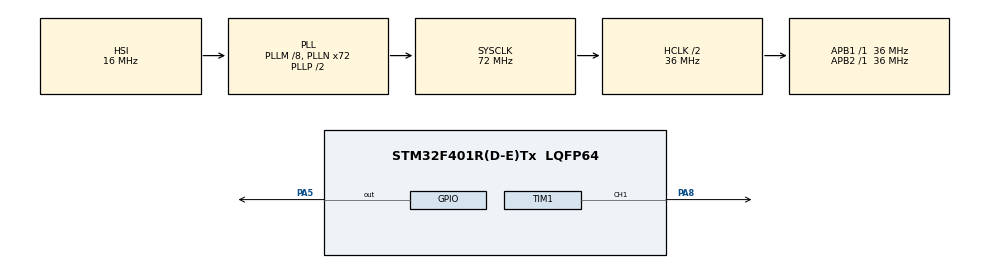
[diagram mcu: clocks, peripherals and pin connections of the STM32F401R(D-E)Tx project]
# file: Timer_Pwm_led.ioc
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Mcu.Family=STM32F4
Mcu.Name=STM32F401R(D-E)Tx
Mcu.Package=LQFP64
NVIC.PriorityGroup=NVIC_PRIORITYGROUP_4
PA13.Mode=Serial_Wire
PA13.Signal=SYS_JTMS-SWDIO
PA14.Mode=Serial_Wire
PA14.Signal=SYS_JTCK-SWCLK
PA5.Signal=GPIO_Output
PA8.Signal=S_TIM1_CH1
PH0\ -\ OSC_IN.Mode=HSE-External-Clock-Source
PH0\ -\ OSC_IN.Signal=RCC_OSC_IN
PH1\ -\ OSC_OUT.Mode=HSE-External-Clock-Source
PH1\ -\ OSC_OUT.Signal=RCC_OSC_OUT
ProjectManager.HeapSize=0x200
ProjectManager.StackSize=0x400
ProjectManager.TargetToolchain=STM32CubeIDE
RCC.48MHZClocksFreq_Value=36000000
RCC.AHBCLKDivider=RCC_SYSCLK_DIV2
RCC.AHBFreq_Value=36000000
RCC.APB1Freq_Value=36000000
RCC.APB1TimFreq_Value=36000000
RCC.APB2Freq_Value=36000000
RCC.APB2TimFreq_Value=36000000
RCC.CortexFreq_Value=36000000
RCC.HCLKFreq_Value=36000000
RCC.HSE_VALUE=25000000
RCC.HSI_VALUE=16000000
RCC.LSE_VALUE=32768
RCC.PLLM=8
RCC.PLLN=72
RCC.SYSCLKFreq_VALUE=72000000
RCC.SYSCLKSource=RCC_SYSCLKSOURCE_PLLCLK
RCC.VCOOutputFreq_Value=144000000
SH.S_TIM1_CH1.0=TIM1_CH1,PWM Generation1 CH1
TIM1.Channel-PWM\ Generation1\ CH1=TIM_CHANNEL_1
board=custom

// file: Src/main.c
/* USER CODE BEGIN Header */
/**
  ******************************************************************************
  * @file           : main.c
  * @brief          : Main program body
  ******************************************************************************
  * @attention
  *
  * <h2><center>&copy; Copyright (c) 2021 STMicroelectronics.
  * All rights reserved.</center></h2>
  *
  * This software component is licensed by ST under BSD 3-Clause license,
  * the "License"; You may not use this file except in compliance with the
  * License. You may obtain a copy of the License at:
  *                        opensource.org/licenses/BSD-3-Clause
  *
  ******************************************************************************
  */
/* USER CODE END Header */
#include "main.h"

TIM_HandleTypeDef htim1;

void SystemClock_Config(void);
static void MX_GPIO_Init(void);
static void MX_TIM1_Init(void);

/* USER CODE BEGIN 0 */
int32_t bright=0;

/* USER CODE END 0 */

int main(void)
{

  /* MCU Configuration--------------------------------------------------------*/

  /* Reset of all peripherals, Initializes the Flash interface and the Systick. */
  HAL_Init();

  /* Configure the system clock */
  SystemClock_Config();

  /* Initialize all configured peripherals */
  MX_GPIO_Init();
  MX_TIM1_Init();
  /* USER CODE BEGIN 2 */

  HAL_TIM_PWM_Start(&htim1, TIM_CHANNEL_1);

  /* USER CODE END 2 */

  /* Infinite loop */
  while (1)
  {

    /* USER CODE BEGIN 3 */
	  while(bright < htim1.Init.Period){

	 	  bright+=100;
	 	  __HAL_TIM_SET_COMPARE(&htim1,TIM_CHANNEL_1,bright);

	 	  HAL_Delay(1);
	 	  }
	 	  while(bright > 0){
	 		  bright-=100;
	 		  __HAL_TIM_SET_COMPARE(&htim1,TIM_CHANNEL_1,bright);

	 		  HAL_Delay(1);
	 	  }

  }
  /* USER CODE END 3 */
}

void SystemClock_Config(void)
{
  RCC_OscInitTypeDef RCC_OscInitStruct = {0};
  RCC_ClkInitTypeDef RCC_ClkInitStruct = {0};

  /** Configure the main internal regulator output voltage
  */
  __HAL_RCC_PWR_CLK_ENABLE();
  __HAL_PWR_VOLTAGESCALING_CONFIG(PWR_REGULATOR_VOLTAGE_SCALE2);
  /** Initializes the RCC Oscillators according to the specified parameters
  * in the RCC_OscInitTypeDef structure.
  */
  RCC_OscInitStruct.OscillatorType = RCC_OSCILLATORTYPE_HSI;
  RCC_OscInitStruct.HSIState = RCC_HSI_ON;
  RCC_OscInitStruct.HSICalibrationValue = RCC_HSICALIBRATION_DEFAULT;
  RCC_OscInitStruct.PLL.PLLState = RCC_PLL_ON;
  RCC_OscInitStruct.PLL.PLLSource = RCC_PLLSOURCE_HSI;
  RCC_OscInitStruct.PLL.PLLM = 8;
  RCC_OscInitStruct.PLL.PLLN = 72;
  RCC_OscInitStruct.PLL.PLLP = RCC_PLLP_DIV2;
  RCC_OscInitStruct.PLL.PLLQ = 4;
  if (HAL_RCC_OscConfig(&RCC_OscInitStruct) != HAL_OK)
  {
    Error_Handler();
  }
  /** Initializes the CPU, AHB and APB buses clocks
  */
  RCC_ClkInitStruct.ClockType = RCC_CLOCKTYPE_HCLK|RCC_CLOCKTYPE_SYSCLK
                              |RCC_CLOCKTYPE_PCLK1|RCC_CLOCKTYPE_PCLK2;
  RCC_ClkInitStruct.SYSCLKSource = RCC_SYSCLKSOURCE_PLLCLK;
  RCC_ClkInitStruct.AHBCLKDivider = RCC_SYSCLK_DIV2;
  RCC_ClkInitStruct.APB1CLKDivider = RCC_HCLK_DIV1;
  RCC_ClkInitStruct.APB2CLKDivider = RCC_HCLK_DIV1;

  if (HAL_RCC_ClockConfig(&RCC_ClkInitStruct, FLASH_LATENCY_1) != HAL_OK)
  {
    Error_Handler();
  }
}

static void MX_TIM1_Init(void)
{

  TIM_MasterConfigTypeDef sMasterConfig = {0};
  TIM_OC_InitTypeDef sConfigOC = {0};
  TIM_BreakDeadTimeConfigTypeDef sBreakDeadTimeConfig = {0};

  htim1.Instance = TIM1;
  htim1.Init.Prescaler = 0;
  htim1.Init.CounterMode = TIM_COUNTERMODE_UP;
  htim1.Init.Period = 65535;
  htim1.Init.ClockDivision = TIM_CLOCKDIVISION_DIV1;
  htim1.Init.RepetitionCounter = 0;
  htim1.Init.AutoReloadPreload = TIM_AUTORELOAD_PRELOAD_DISABLE;
  if (HAL_TIM_PWM_Init(&htim1) != HAL_OK)
  {
    Error_Handler();
  }
  sMasterConfig.MasterOutputTrigger = TIM_TRGO_RESET;
  sMasterConfig.MasterSlaveMode = TIM_MASTERSLAVEMODE_DISABLE;
  if (HAL_TIMEx_MasterConfigSynchronization(&htim1, &sMasterConfig) != HAL_OK)
  {
    Error_Handler();
  }
  sConfigOC.OCMode = TIM_OCMODE_PWM1;
  sConfigOC.Pulse = 0;
  sConfigOC.OCPolarity = TIM_OCPOLARITY_HIGH;
  sConfigOC.OCNPolarity = TIM_OCNPOLARITY_HIGH;
  sConfigOC.OCFastMode = TIM_OCFAST_DISABLE;
  sConfigOC.OCIdleState = TIM_OCIDLESTATE_RESET;
  sConfigOC.OCNIdleState = TIM_OCNIDLESTATE_RESET;
  if (HAL_TIM_PWM_ConfigChannel(&htim1, &sConfigOC, TIM_CHANNEL_1) != HAL_OK)
  {
    Error_Handler();
  }
  sBreakDeadTimeConfig.OffStateRunMode = TIM_OSSR_DISABLE;
  sBreakDeadTimeConfig.OffStateIDLEMode = TIM_OSSI_DISABLE;
  sBreakDeadTimeConfig.LockLevel = TIM_LOCKLEVEL_OFF;
  sBreakDeadTimeConfig.DeadTime = 0;
  sBreakDeadTimeConfig.BreakState = TIM_BREAK_DISABLE;
  sBreakDeadTimeConfig.BreakPolarity = TIM_BREAKPOLARITY_HIGH;
  sBreakDeadTimeConfig.AutomaticOutput = TIM_AUTOMATICOUTPUT_DISABLE;
  if (HAL_TIMEx_ConfigBreakDeadTime(&htim1, &sBreakDeadTimeConfig) != HAL_OK)
  {
    Error_Handler();
  }
  HAL_TIM_MspPostInit(&htim1);

}

static void MX_GPIO_Init(void)
{
  GPIO_InitTypeDef GPIO_InitStruct = {0};

  /* GPIO Ports Clock Enable */
  __HAL_RCC_GPIOH_CLK_ENABLE();
  __HAL_RCC_GPIOA_CLK_ENABLE();

  /*Configure GPIO pin Output Level */
  HAL_GPIO_WritePin(GPIOA, GPIO_PIN_5, GPIO_PIN_RESET);

  /*Configure GPIO pin : PA5 */
  GPIO_InitStruct.Pin = GPIO_PIN_5;
  GPIO_InitStruct.Mode = GPIO_MODE_OUTPUT_PP;
  GPIO_InitStruct.Pull = GPIO_NOPULL;
  GPIO_InitStruct.Speed = GPIO_SPEED_FREQ_LOW;
  HAL_GPIO_Init(GPIOA, &GPIO_InitStruct);

}

void Error_Handler(void)
{
  __disable_irq();
  while (1)
  {
  }
}

/************************ (C) COPYRIGHT STMicroelectronics *****END OF FILE****/
